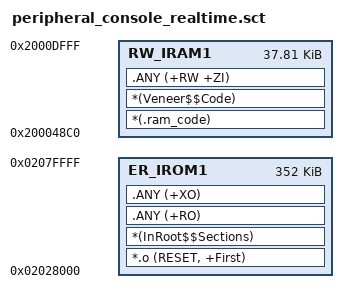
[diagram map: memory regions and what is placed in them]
; *************************************************************
; *** Scatter-Loading Description File generated by uVision ***
; *************************************************************

LR_IROM1 0x02028000 0x00058000  {    ; load region size_region
  ER_IROM1 0x02028000 0x00058000  {  ; load address = execution address
   *.o (RESET, +First)
   *(InRoot$$Sections)
   .ANY (+RO)
   .ANY (+XO)
  }
RW_IRAM1 0x200048C0 0x00009740 {  ; RW data
   *(.ram_code)
   *(Veneer$$Code)
   .ANY (+RW +ZI)
  }
}

